# nrf9230_enga_application register map
Vendor: Nordic Semiconductor; Series: nRF92; File version: 1
CPU: CM33 r0p4, little endian, MPU, FPU, 3 interrupt priority bits, 480 interrupts, 4 SAU regions
Registers are 32-bit, read-write, reset 0x0 unless marked. A register's access mark holds for its fields unless they carry their own. Offsets are from the block's base; [hi:lo] are bit positions; lines under a group give offsets from that group; {n}, {i} and the like mark numbered series; 'fields as' and 'values as' point back to an identical list.

## UICR_NS — User information configuration registers
Base 0x0FFF8000
{0x0+8i} MEM[{i}] (i=0..15) group — Unspecified
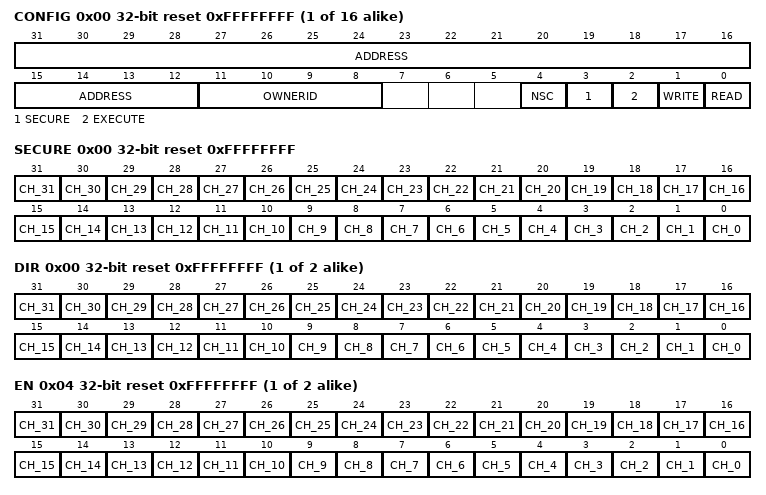
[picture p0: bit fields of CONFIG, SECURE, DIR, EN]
  0x00 CONFIG reset 0xFFFFFFFF — Description cluster: Memory configuration of the memory region
    [31:12] ADDRESS — Memory region start address, bits [31:12]
    [11:8] OWNERID — Memory owner identification
    [4] NSC
      1=Disabled (Memory region is not non-secure callable); 0=Enabled (Memory region is non-secure callable)
    [3] SECURE
      1=Secure (Non-secure access to MEM[n] is not allowed); 0=Non-secure access to MEM[n] is allowed
    [2] EXECUTE
      1=NotAllowed (SW execution from MEM[n] is not allowed); 0=Allowed (SW execution from MEM[n] is allowed)
    [1] WRITE
      1=NotAllowed (Write access to MEM[n] is not allowed); 0=Allowed (Write access to MEM[n] is allowed)
    [0] READ
      1=NotAllowed (Read access to MEM[n] is not allowed); 0=Allowed (Read access to MEM[n] is allowed)
  0x04 SIZE reset 0xFFFFFFFF — Description cluster: Size of the memory region
    [31:0] SIZE — Memory size in bytes
{0x100+4i} PERIPH[{i}] (i=0..191) group — Unspecified
  0x00 CONFIG reset 0xFFFFFFFF — Description cluster: Peripheral configuration
    [31:12] ADDRESS — Peripheral address, bits [31:12]
    [11:8] PROCESSOR — Processor ID of the processor that will receive the peripheral IRQ
    [5] DMASEC — Security attribution for the DMA transfer
      1=Secure (DMA transfers initiated by this peripheral have the secure attribute set); 0=NonSecure (DMA transfers initiated by this peripheral have the non-secure attribute set)
    [3] SECURE — Peripheral security mapping
      1=Secure (Peripheral is mapped in secure peripheral address space); 0=NonSecure (Peripheral is mapped in non-secure peripheral address space.)
{0x480+0xC*i} GPIOTE[{i}] (i=0..3) group — Unspecified
  0x00 INSTANCE reset 0xFFFFFFFF — Description cluster: Address of the GPIOTE instance associated with GPIOTE[n]
    [31:0] ADDRESS — Instance address
  0x04 CH group — Unspecified
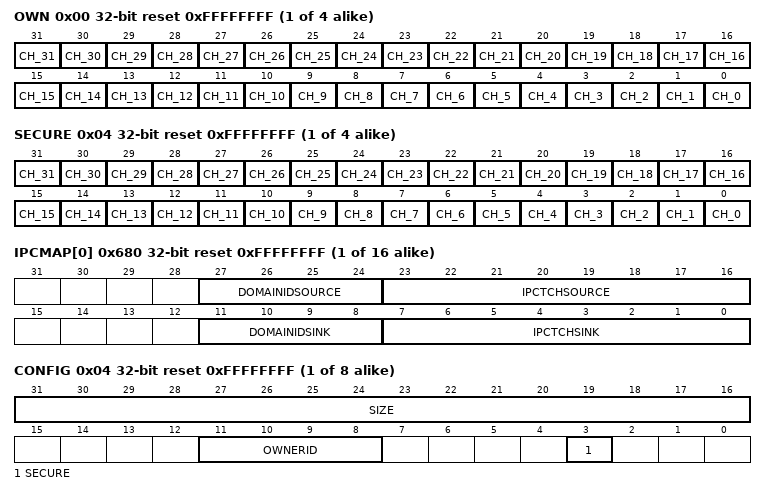
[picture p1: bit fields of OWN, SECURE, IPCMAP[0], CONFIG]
    0x00 OWN reset 0xFFFFFFFF — Description cluster: Request ownership of the channels of GPIOTE[n]
      [n] CH_{n} (n=0..31) — Channel number
        1=NotOwn (Do not own the channel {n}); 0=Own (Own the channel {n})
    0x04 SECURE reset 0xFFFFFFFF — Description cluster: Request permission for the channels of GPIOTE[n]
      [n] CH_{n} (n=0..31) — Channel number
        1=Secure (The channel {n} is secure); 0=NonSecure (The channel {n} is non-secure)
0x4B0 IPCT group — Unspecified
  0x00 LOCAL group — Unspecified
    0x00 CH group — Unspecified
      0x00 SECURE reset 0xFFFFFFFF — Request permission for the channels of IPCT in the local domain
        fields as GPIOTE[0].CH.SECURE
    0x04 INTERRUPT group — Unspecified
      0x00 SECURE reset 0xFFFFFFFF — Request permission for the interrupts of IPCT in the local domain
        [n] INT_{n} (n=0..31) — Interrupt number
          1=Secure (The interrupt {n} is secure); 0=NonSecure (The interrupt {n} is non-secure)
  {0x8+0x14*j} GLOBAL[{j}] (j=0..1) group — Unspecified
    0x00 INSTANCE reset 0xFFFFFFFF — Description cluster: Address of the IPCT instance associated with IPCT[n].GLOBAL
      [31:0] ADDRESS — Instance address
    0x04 CH group — Unspecified
      0x00 OWN reset 0xFFFFFFFF — Description cluster: Request ownership of the channels of IPCT[n] in Global domain
        fields as GPIOTE[0].CH.OWN
      0x04 SECURE reset 0xFFFFFFFF — Description cluster: Request permission for the channels of IPCT[n] in Global domain
        fields as GPIOTE[0].CH.SECURE
    0x0C INTERRUPT group — Unspecified
      0x00 OWN reset 0xFFFFFFFF — Description cluster: Request ownership of the interrupts of IPCT[n] in Global domain
        [n] INT_{n} (n=0..31) — Interrupt number
          1=NotOwn (Do not own the interrupt {n}); 0=Own (Own the interrupt {n})
      0x04 SECURE reset 0xFFFFFFFF — Description cluster: Request permission for the interrupts of IPCT[n] in Global domain
        fields as IPCT.LOCAL.INTERRUPT.SECURE
0x4E0 DPPI group — Unspecified
  {0x0+0x14*j} LOCAL[{j}] (j=0..1) group — Unspecified
    0x00 INSTANCE reset 0xFFFFFFFF — Description cluster: Address of the DPPI instance associated with DPPI[n].LOCAL
      [31:0] ADDRESS — Instance address
    0x04 CH group — Unspecified
      0x00 SECURE reset 0xFFFFFFFF — Description cluster: Request permission for the channels of DPPI[n] in the local domain
        fields as GPIOTE[0].CH.SECURE
      0x04 LINK group — Unspecified
        0x00 DIR reset 0xFFFFFFFF — Description cluster: Request linking the channels of DPPI[n] in local domain as source or sink
          [n] CH_{n} (n=0..31) — Link direction
            1=Source (The channel {n} is linked as source); 0=Sink (The channel {n} is linked as sink)
        0x04 EN reset 0xFFFFFFFF — Description cluster: Request linking of the channels of DPPI[n] in the local domain
          [n] CH_{n} (n=0..31) — Link enable
            1=Disabled (The channel {n} is disabled); 0=Enabled (The channel {n} is enabled)
    0x10 CHG group — Unspecified
      0x00 SECURE reset 0xFFFFFFFF — Description cluster: Request permission for the channel groups of DPPI[n] in the local domain
        [n] CHG_{n} (n=0..31) — Channel group number
          1=Secure (The channel group {n} is secure); 0=NonSecure (The channel group {n} is non-secure)
  {0x28+0x1C*j} GLOBAL[{j}] (j=0..11) group — Unspecified
    0x00 INSTANCE reset 0xFFFFFFFF — Description cluster: Address of the DPPI instance associated with DPPI[n].GLOBAL
      [31:0] ADDRESS — Instance address
    0x04 CH group — Unspecified
      0x00 OWN reset 0xFFFFFFFF — Description cluster: Request ownership of the channels of DPPI[n] in Global Domain
        fields as GPIOTE[0].CH.OWN
      0x04 SECURE reset 0xFFFFFFFF — Description cluster: Request permission for the channels of DPPI[n] in Global domain
        fields as GPIOTE[0].CH.SECURE
      0x08 LINK group — Unspecified
        0x00 DIR reset 0xFFFFFFFF — Description cluster: Request linking the channels of DPPI[n] in Global domain as source or sink
          fields as DPPI.LOCAL[0].CH.LINK.DIR
        0x04 EN reset 0xFFFFFFFF — Description cluster: Request linking of the channels of DPPI[n] in the Global domain
          fields as DPPI.LOCAL[0].CH.LINK.EN
    0x14 CHG group — Unspecified
      0x00 OWN reset 0xFFFFFFFF — Description cluster: Request ownership of the channel groups of DPPI[n] in Global domain
        [n] CHG_{n} (n=0..31) — Channel group number
          1=NotOwn (Do not own the channel group {n}); 0=Own (Own the channel group {n})
      0x04 SECURE reset 0xFFFFFFFF — Description cluster: Request permission for the channel groups of DPPI[n] in Global domain
        fields as DPPI.LOCAL[0].CHG.SECURE
0x660 GRTC group — Unspecified
  0x00 CC group — Unspecified
    0x00 OWN reset 0xFFFFFFFF — Request ownership of the CCs of GRTCGRTC
      [n] CC_{n} (n=0..15) — Capture/compare register number
        1=NotOwn (Do not own the CC register {n}); 0=Own (Own the CC register {n})
    0x04 SECURE reset 0xFFFFFFFF — Request permission for the CCs of GRTC
      [n] CC_{n} (n=0..15) — Capture/compare register number
        1=Secure (The CC register {n} is secure); 0=NonSecure (The CC register {n} is non-secure)
{0x680+4i} IPCMAP[{i}] (i=0..15) reset 0xFFFFFFFF — Description collection: Request configuration for the channel n of IPCMAP
  [27:24] DOMAINIDSOURCE — Domain ID (source side)
  [23:16] IPCTCHSOURCE — IPCT channel number (source side)
  [11:8] DOMAINIDSINK — Domain ID (sink side)
  [7:0] IPCTCHSINK — IPCT channel number (sink side)
{0x700+8i} MAILBOX[{i}] (i=0..7) group — Unspecified
  0x00 ADDRESS reset 0xFFFFFFFF — Description cluster: Memory start address of mailbox n
    [31:0] ADDRESS — Memory address
  0x04 CONFIG reset 0xFFFFFFFF — Description cluster: Configuration of mailbox n
    [31:16] SIZE — Memory size
    [11:8] OWNERID — Remote owner identification
    [3] SECURE — Permission
      1=Secure (The mailbox memory is secure); 0=NonSecure (The mailbox memory is non-secure)
0x740 TRACE group — Unspecified
  0x00 ETBSINK group — Unspecified
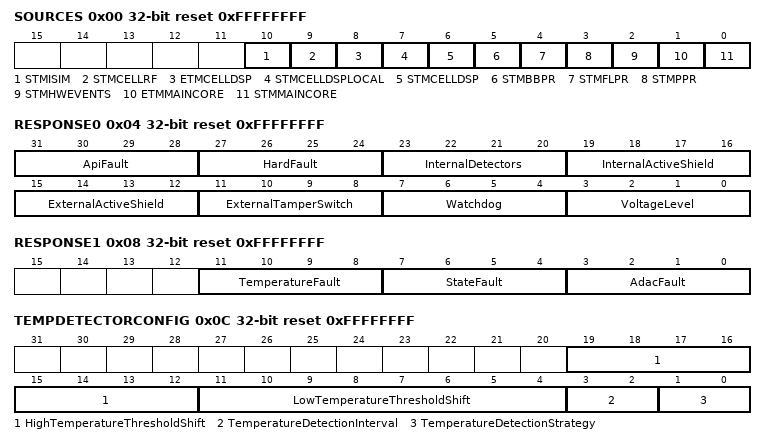
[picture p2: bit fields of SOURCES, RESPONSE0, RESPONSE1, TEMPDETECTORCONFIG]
    0x00 SOURCES reset 0xFFFFFFFF — Unspecified
      [all] fields
        1=NotRequested; 0=Requested
      [10] STMISIM — STM trace from iSIM secure core
      [9] STMCELLRF — STM trace from Cellular RF CPU
      [8] ETMCELLDSP — ETM trace from Cellular DSP
      [7] STMCELLDSPLOCAL — STM trace from Cellular DSP local STM
      [6] STMCELLDSP — STM trace from Cellular DSP
      [5] STMBBPR — STM trace from BBPR CPU
      [4] STMFLPR — STM trace from FLPR CPU
      [3] STMPPR — STM trace from PPR CPU
      [2] STMHWEVENTS — STM HW events trace
      [1] ETMMAINCORE — ETM trace from the domain main CPU
      [0] STMMAINCORE — STM trace from the domain main CPU
  0x04 TPIUSINK group — Unspecified
    0x00 SOURCES reset 0xFFFFFFFF — Unspecified
      fields as TRACE.ETBSINK.SOURCES
  0x08 ETRSINK group — Unspecified
    0x00 SOURCES reset 0xFFFFFFFF — Unspecified
      fields as TRACE.ETBSINK.SOURCES
  0x0C PORTCONFIG reset 0xFFFFFFFF — Trace port speed configuration
    [1:0] PORTCONFIG
      3=FullSpeed; 2=HalfSpeed; 1=QuarterSpeed (One quarter speed); 0=EightSpeed (One eigth speed)
0x760 TAMPER group — Unspecified
  0x00 DETECTION group — Tamper policy configuration for detected security events.
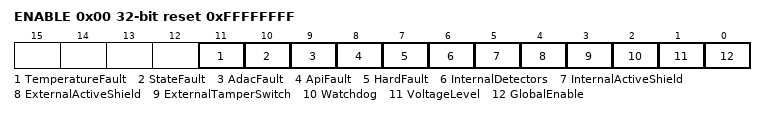
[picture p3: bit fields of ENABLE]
    0x00 ENABLE reset 0xFFFFFFFF — Unspecified
      [11] TemperatureFault — Configure if tamper prevention should react when on-die temperature exceeds a valid range.
        0=Enable invalid out-of-range temperature detector; 1=Disable invalid out-of-range temperature detector
      [10] StateFault — Configure if tamper prevention should react on invalid firmware execution state.
        0=Enable invalid firmware execution state detector; 1=Disable invalid firmware execution state detector
      [9] AdacFault — Configure if tamper prevention should react on invalid ADAC usage.
        0=Enable invalid ADAC usage detector; 1=Disable invalid ADAC usage detector
      [8] ApiFault — Configure if tamper prevention should react on invalid API usage.
        0=Enable API fault detector; 1=Disable API fault detector
      [7] HardFault — Configure if tamper prevention should react on hard faults.
        0=Enable hard fault detector; 1=Disable hard fault detector
      [6] InternalDetectors — Reserved field, as internal detectors are always enabled.
      [5] InternalActiveShield — Enable internal active shield detector.
        0=Enable internal active shield detector; 1=Disable internal active shield detector
      [4] ExternalActiveShield — Enable external active shield detector.
        0=Enable external active shield detector; 1=Disable external active shield detector
      [3] ExternalTamperSwitch — Enable external tamper switch detector.
        0=Enable external tamper switch detector; 1=Disable external tamper switch detector
      [2] Watchdog — Reserved field, as watchdog timer is always enabled.
      [1] VoltageLevel — Enable voltage level detectors (VDETs) on supply lines. An automatic system reset is issued when voltage on the corresponding supply line is too low.
        0=Enable voltage level detectors; 1=Disable voltage level detectors
      [0] GlobalEnable — Enable tamper detection. When disabled all tamper enable and policy switches are ignored.
        0=Enable tamper detection; 1=Disable tamper detection
    0x04 RESPONSE0 reset 0xFFFFFFFF — Unspecified
      [31:28] ApiFault — Configure tamper policy for invalid API usage.
        1=Manual (Block secure services until requested to unblock secure services. Allows user application to take required actions.); 2=PowerCycle (Block secure services until power cycling the device.); 3=15Minutes (Block secure services until device has been powered and idle for 15 minutes.); 4=1Hour (Block secure services until device has been powered and idle for one hour.); 10=LCSDiscarded (Transition to LCS Discarded. Warning, this bricks the device permanently.); 15=ResetOnly (No addition penalty besides the automatic reset.)
      [27:24] HardFault — Configure tamper policy for hard fault.
        values as ApiFault
      [23:20] InternalDetectors — Configure tamper policy for internal detectors including glitch detector, signal protector and CRACEN detector. See for more information. An automatic reset is issued upon detection.
        2=PowerCycle (Block secure services until power cycling the device.); 3=15Minutes (Block secure services until device has been powered and idle for 15 minutes.); 4=1Hour (Block secure services until device has been powered and idle for one hour.); 10=LCSDiscarded (Transition to LCS Discarded. Warning, this bricks the device permanently.); 15=ResetOnly (No addition penalty besides the automatic reset.)
      [19:16] InternalActiveShield — Configure tamper policy for internal active shield.
        values as ApiFault
      [15:12] ExternalActiveShield — Configure tamper policy for external active shield. BICR is used to specify which channels (GPIOs) are enabled.
        values as ApiFault
      [11:8] ExternalTamperSwitch — Configure tamper policy for external tamper switch.
        values as ApiFault
      [7:4] Watchdog — Configure tamper policy for watchdog timer.
        values as InternalDetectors
      [3:0] VoltageLevel — Configure tamper policy for invalid voltage level on supply lines.
        values as InternalDetectors
    0x08 RESPONSE1 reset 0xFFFFFFFF — Unspecified
      [all] fields
        values as TAMPER.DETECTION.RESPONSE0.ApiFault
      [11:8] TemperatureFault — Configure out-of-range on-die temperature tamper policy. A reset is required to continue providing secure services once the on-temperature is within valid operating conditions again. This reset is automatically triggered by the secure domain.
      [7:4] StateFault — Configure tamper policy for illegal firmware execution state. Automatic reset is issued be secure domain before secure services are permitted again.
      [3:0] AdacFault — Configure tamper policy for invalid ADAC usage.
    0x0C TEMPDETECTORCONFIG reset 0xFFFFFFFF — Unspecified
      [19:12] HighTemperatureThresholdShift — High temperature detection threshold shift in degrees Celsius. The high temperature threshold is calculated by subtracting the threshold shift from the maximum operating temperature of the SoC.
      [11:4] LowTemperatureThresholdShift — Low temperature detection threshold shift in degrees Celsius. The low temperature threshold is calculated by adding the threshold shift to the minimum operating temperature of the SoC.
      [3:2] TemperatureDetectionInterval — Configure interval for on-die temperature reading if periodic reading is enabled.
        0=1Minute (On-die temperature sensor is read with one minute intervals.); 2=15Minutes (On-die temperature sensor is read with 15 minutes intervals.); 3=1Hour (On-die temperature sensor is read with one hour intervals.)
      [1:0] TemperatureDetectionStrategy — Configure when on-die temperature sensor should check the temperature.
        1=Periodically (On-die temperature sensor is read periodically with selected interval.); 2=OnServiceCallAndPeriodically (On-die temperature sensor is read before each secure service call and periodically with selected interval.); 3=OnServiceCallOnly (On-die temperature sensor is read before each secure service call.)
  0x10 COUNTERMEASURES group — Configuration of countermeasures.
    0x00 ENABLE reset 0xFFFFFFFF — Unspecified
      [9] ClockDithering — Configure the clock dithering countermeasure. When enabled clock will be randomly jittered based on TRNG.
        0=Enable countermeasure; 1=Disable countermeasure
      [8] KEYLOAD — Configure countermeasure for verifying if cryptography key is loaded correctly into CRACEN.
        0=Enable countermeasure; 1=Disable countermeasure
      [7] DFAECC — Reserved for configuration of Differential Fault Analysis countermeasure for CRACEN ECC.
      [6] DFASM4 — Reserved for configuration of Differential Fault Analysis countermeasure for CRACEN SM4.
      [5] DFAPK — Reserved for configuration of Differential Fault Analysis countermeasure for CRACEN PK.
      [4] DFAAES — Reserved for configuration of Differential Fault Analysis countermeasure for CRACEN AES.
      [3] DPAECC — Reserved for configuration of Differential Power Analysis countermeasure for CRACEN ECC.
      [2] DPASM4 — Configure Differential Power Analysis countermeasure for CRACEN SM4.
        0=Enable countermeasure; 1=Disable countermeasure
      [1] DPAPK — Configure Differential Power Analysis countermeasure for CRACEN PK.
        0=Enable countermeasure; 1=Disable countermeasure
      [0] DPAAES — Configure Differential Power Analysis countermeasure for CRACEN AES.
        0=Enable countermeasure; 1=Disable countermeasure
0x780 INITSVTOR reset 0xFFFFFFFF — Initial value of the secure VTOR (Vector Table Offset Register) after CPU reset.
  [31:0] INITSVTOR — Initial value of the VTOR.
0x784 INITNSVTOR reset 0xFFFFFFFF — Initial value of the non-secure VTOR (Vector Table Offset Register).
  [31:0] INITNSVTOR — Initial value of the VTOR.
0x7FC PTREXTUICR reset 0xFFFFFFFF — Pointer to extended UICR.

## Notices in the file
Copyright (c) 2010 - 2024, Nordic Semiconductor ASA
All rights reserved.
Redistribution and use in source and binary forms, with or without modification,
are permitted provided that the following conditions are met:
1. Redistributions of source code must retain the above copyright notice, this
list of conditions and the following disclaimer.
2. Redistributions in binary form, except as embedded into a Nordic
Semiconductor ASA integrated circuit in a product or a software update for
such product, must reproduce the above copyright notice, this list of
conditions and the following disclaimer in the documentation and/or other
materials provided with the distribution.
3. Neither the name of Nordic Semiconductor ASA nor the names of its
contributors may be used to endorse or promote products derived from this
software without specific prior written permission.
4. This software, with or without modification, must only be used with a
Nordic Semiconductor ASA integrated circuit.
5. Any software provided in binary form under this license must not be reverse
engineered, decompiled, modified and/or disassembled.
THIS SOFTWARE IS PROVIDED BY NORDIC SEMICONDUCTOR ASA "AS IS" AND ANY EXPRESS
OR IMPLIED WARRANTIES, INCLUDING, BUT NOT LIMITED TO, THE IMPLIED WARRANTIES
OF MERCHANTABILITY, NONINFRINGEMENT, AND FITNESS FOR A PARTICULAR PURPOSE ARE
DISCLAIMED. IN NO EVENT SHALL NORDIC SEMICONDUCTOR ASA OR CONTRIBUTORS BE
LIABLE FOR ANY DIRECT, INDIRECT, INCIDENTAL, SPECIAL, EXEMPLARY, OR
CONSEQUENTIAL DAMAGES (INCLUDING, BUT NOT LIMITED TO, PROCUREMENT OF SUBSTITUTE
GOODS OR SERVICES; LOSS OF USE, DATA, OR PROFITS; OR BUSINESS INTERRUPTION)
HOWEVER CAUSED AND ON ANY THEORY OF LIABILITY, WHETHER IN CONTRACT, STRICT
LIABILITY, OR TORT (INCLUDING NEGLIGENCE OR OTHERWISE) ARISING IN ANY WAY OUT
OF THE USE OF THIS SOFTWARE, EVEN IF ADVISED OF THE POSSIBILITY OF SUCH DAMAGE.
